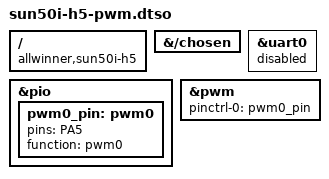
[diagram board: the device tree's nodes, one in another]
/dts-v1/;
/plugin/;

/ {
	compatible = "allwinner,sun50i-h5";

	fragment@0 {
		target-path = "/chosen";
		__overlay__ {
			/delete-property/ stdout-path;
		};
	};

	fragment@1 {
		target = <&uart0>;
		__overlay__ {
			status = "disabled";
		};
	};

	fragment@2 {
		target = <&pio>;
		__overlay__ {
			pwm0_pin: pwm0 {
				pins = "PA5";
				function = "pwm0";
			};
		};
	};

	fragment@3 {
		target = <&pwm>;
		__overlay__ {
			pinctrl-names = "default";
			pinctrl-0 = <&pwm0_pin>;
			status = "okay";
		};
	};
};
